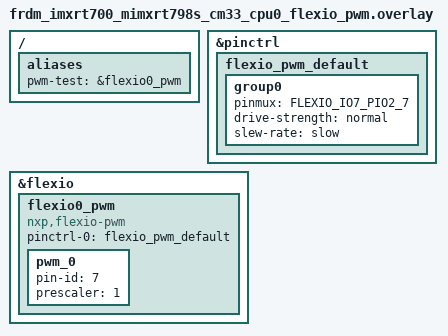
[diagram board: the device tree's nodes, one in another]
/*
 * SPDX-FileCopyrightText: Copyright 2026 NXP
 *
 * SPDX-License-Identifier: Apache-2.0
 */

/* FLEXIO_D7 on J64-8 (PIO2_7) */
&pinctrl {
	flexio_pwm_default: flexio_pwm_default {
		group0 {
			pinmux = <FLEXIO_IO7_PIO2_7>;
			drive-strength = "normal";
			slew-rate = "slow";
		};
	};
};

/ {
	aliases {
		pwm-test = &flexio0_pwm;
	};
};

&flexio {
	status = "okay";

	flexio0_pwm: flexio0_pwm {
		compatible = "nxp,flexio-pwm";
		#pwm-cells = <3>;
		status = "okay";
		pinctrl-0 = <&flexio_pwm_default>;
		pinctrl-names = "default";

		pwm_0 {
			pin-id = <7>;
			prescaler = <1>;
		};
	};
};
